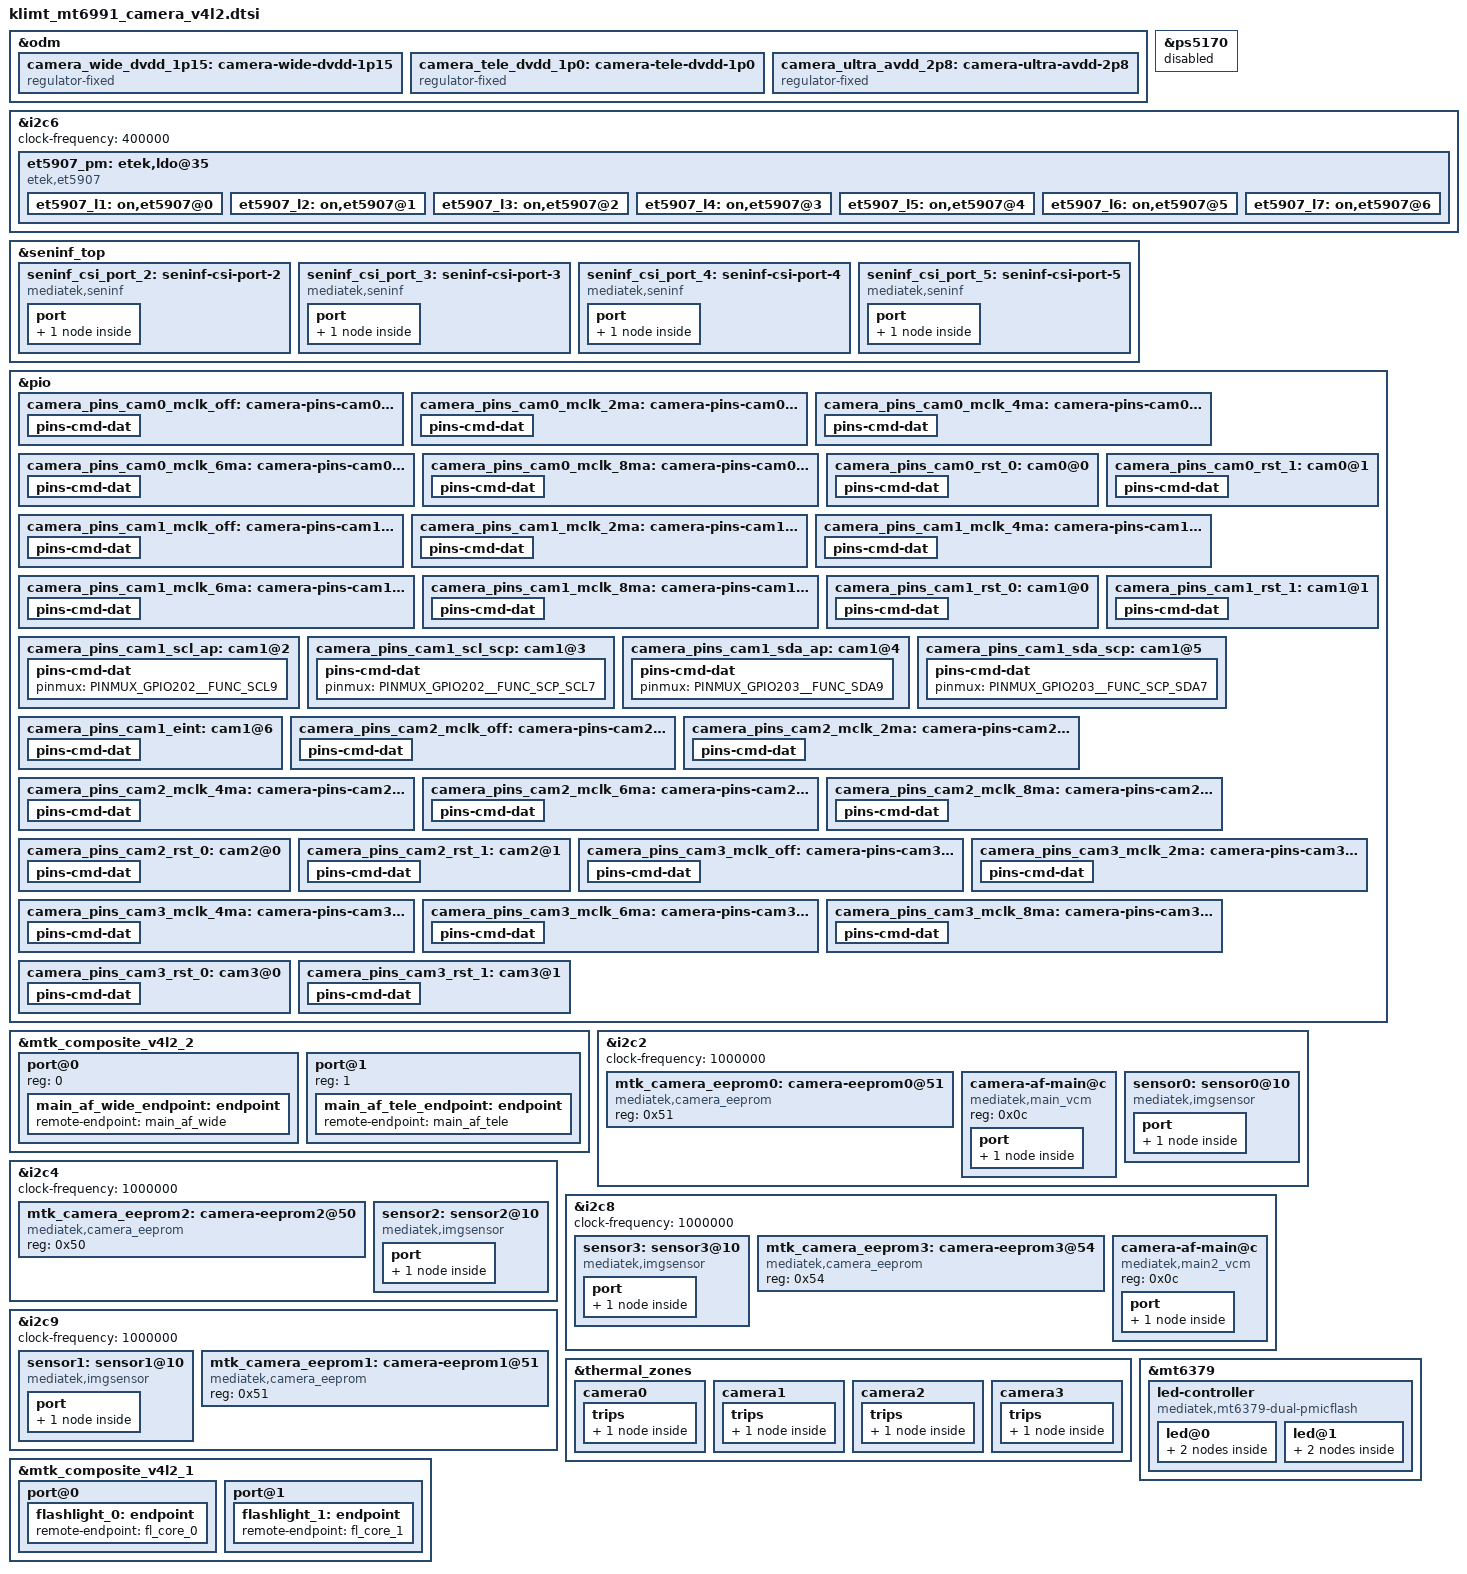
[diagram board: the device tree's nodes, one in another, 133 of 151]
// SPDX-License-Identifier: GPL-2.0
/* Copyright (c) 2023 MediaTek Inc. */
#include <dt-bindings/clock/mt6991-clk.h>
#include <dt-bindings/leds/common.h>
#include <dt-bindings/mfd/mt6379.h>

/* CAMERA GPIO fixed to regulator */
&odm {
	camera_wide_dvdd_1p15: camera-wide-dvdd-1p15 {
		compatible = "regulator-fixed";
		regulator-name = "camera-wide-dvdd-1p15";
		regulator-min-microvolt = <1150000>;
		regulator-max-microvolt = <1150000>;
		gpio = <&pio 180 0x0>;
		enable-active-high;
	};
	camera_tele_dvdd_1p0: camera-tele-dvdd-1p0 {
		compatible = "regulator-fixed";
		regulator-name = "camera-tele-dvdd-1p0";
		regulator-min-microvolt = <1000000>;
		regulator-max-microvolt = <1000000>;
		gpio = <&pio 181 0x0>;
		enable-active-high;
	};
	camera_ultra_avdd_2p8: camera-ultra-avdd-2p8 {
		compatible = "regulator-fixed";
		regulator-name = "camera-ultra-avdd-2p8";
		regulator-min-microvolt = <2800000>;
		regulator-max-microvolt = <2800000>;
		gpio = <&pio 207 0x0>;
		enable-active-high;
	};
};

&ps5170 {
	pinctrl-names = "enable", "disable";
	pinctrl-0 = <&ps_enable>;
	pinctrl-1 = <&ps_disable>;
	status = "disable";
};

&i2c6 {
	#address-cells = <1>;
	#size-cells = <0>;
	clock-frequency = <400000>;

	et5907_pm:etek,ldo@35 {
		compatible = "etek,et5907";
		reg = <0x35>;/*slave address*/
		index = <0>;

		et5907_l1:on,et5907@0{
			offset = /bits/ 16 <0x0000>;
			regulator-name ="et5907-l1";
			regulator-min-microvolt = <496000>;
			regulator-max-microvolt = <2048000>;
			min-dropout-voltage = <225000>;
			init-voltage = <1200000>;
			iout_ua = <650000>;
		};

		et5907_l2:on,et5907@1{
			offset = /bits/ 16 <0x0001>;
			regulator-name ="et5907-l2";
			regulator-min-microvolt = <496000>;
			regulator-max-microvolt = <2048000>;
			min-dropout-voltage = <225000>;
			init-voltage = <1200000>;
			iout_ua = <650000>;
		};

		et5907_l3:on,et5907@2{
			offset = /bits/ 16 <0x0002>;
			regulator-name ="et5907-l3";
			regulator-min-microvolt = <1372000>;
			regulator-max-microvolt = <3412000>;
			min-dropout-voltage = <200000>;
			init-voltage = <2800000>;
			iout_ua = <650000>;
		};

		et5907_l4:on,et5907@3{
			offset = /bits/ 16 <0x0003>;
			regulator-name ="et5907-l4";
			regulator-min-microvolt = <1372000>;
			regulator-max-microvolt = <3412000>;
			min-dropout-voltage = <200000>;
			init-voltage = <2800000>;
			iout_ua = <650000>;
		};

		et5907_l5:on,et5907@4{
			offset = /bits/ 16 <0x0004>;
			regulator-name ="et5907-l5";
			regulator-min-microvolt = <1372000>;
			regulator-max-microvolt = <3412000>;
			min-dropout-voltage = <300000>;
			init-voltage = <2800000>;
			iout_ua = <650000>;
		};

		et5907_l6:on,et5907@5{
			offset = /bits/ 16 <0x0005>;
			regulator-name ="et5907-l6";
			regulator-min-microvolt = <1372000>;
			regulator-max-microvolt = <3412000>;
			min-dropout-voltage = <300000>;
			init-voltage = <2800000>;
			iout_ua = <650000>;
		};

		et5907_l7:on,et5907@6{
			offset = /bits/ 16 <0x0006>;
			regulator-name ="et5907-l7";
			regulator-min-microvolt = <1372000>;
			regulator-max-microvolt = <3412000>;
			min-dropout-voltage = <300000>;
			init-voltage = <2800000>;
			iout_ua = <650000>;
		};

	};
};

&seninf_top {
		seninf_csi_port_2: seninf-csi-port-2 {
			compatible = "mediatek,seninf";
			csi-port = "2";

			nvmem-cells = <&csi_efuse2>;
			nvmem-cell-names = "rg_csi";

			port {
				seninf_csi_port_2_in: endpoint {
					remote-endpoint = <&sensor3_out>;
				};
			};
		};

		seninf_csi_port_3: seninf-csi-port-3 {
			compatible = "mediatek,seninf";
			csi-port = "3";

			nvmem-cells = <&csi_efuse3>;
			nvmem-cell-names = "rg_csi";

			port {
				seninf_csi_port_3_in: endpoint {
					remote-endpoint = <&sensor1_out>;
				};
			};
		};

		seninf_csi_port_4: seninf-csi-port-4 {
			compatible = "mediatek,seninf";
			csi-port = "4";

			nvmem-cells = <&csi_efuse4>;
			nvmem-cell-names = "rg_csi";

			port {
				seninf_csi_port_4_in: endpoint {
					remote-endpoint = <&sensor0_out>;
				};
			};
		};

		seninf_csi_port_5: seninf-csi-port-5 {
			compatible = "mediatek,seninf";
			csi-port = "5";

			nvmem-cells = <&csi_efuse5>;
			nvmem-cell-names = "rg_csi";

			port {
				seninf_csi_port_5_in: endpoint {
					remote-endpoint = <&sensor2_out>;
				};
			};
		};
};

/* CAMERA GPIO standardization */
&pio {
	camera_pins_cam0_mclk_off: camera-pins-cam0-mclk-off {
		pins-cmd-dat {
			pinmux = <PINMUX_GPIO196__FUNC_GPIO196>;
			drive-strength = <1>;
		};
	};
	camera_pins_cam0_mclk_2ma: camera-pins-cam0-mclk-2ma {
		pins-cmd-dat {
			pinmux = <PINMUX_GPIO196__FUNC_CMMCLK3>;
			drive-strength = <0>;
		};
	};
	camera_pins_cam0_mclk_4ma: camera-pins-cam0-mclk-4ma {
		pins-cmd-dat {
			pinmux = <PINMUX_GPIO196__FUNC_CMMCLK3>;
			drive-strength = <1>;
		};
	};
	camera_pins_cam0_mclk_6ma: camera-pins-cam0-mclk-6ma {
		pins-cmd-dat {
			pinmux = <PINMUX_GPIO196__FUNC_CMMCLK3>;
			drive-strength = <2>;
		};
	};
	camera_pins_cam0_mclk_8ma: camera-pins-cam0-mclk-8ma {
		pins-cmd-dat {
			pinmux = <PINMUX_GPIO196__FUNC_CMMCLK3>;
			drive-strength = <3>;
		};
	};
	camera_pins_cam0_rst_0: cam0@0 {
		pins-cmd-dat {
			pinmux = <PINMUX_GPIO197__FUNC_GPIO197>;
			drive-strength = <0>;
			output-low;
		};
	};
	camera_pins_cam0_rst_1: cam0@1 {
		pins-cmd-dat {
			pinmux = <PINMUX_GPIO197__FUNC_GPIO197>;
			drive-strength = <1>;
			output-high;
		};
	};
	camera_pins_cam1_mclk_off: camera-pins-cam1-mclk-off {
		pins-cmd-dat {
			pinmux = <PINMUX_GPIO79__FUNC_GPIO79>;
			drive-strength = <1>;
		};
	};
	camera_pins_cam1_mclk_2ma: camera-pins-cam1-mclk-2ma {
		pins-cmd-dat {
			pinmux = <PINMUX_GPIO79__FUNC_CMMCLK0>;
			drive-strength = <0>;
		};
	};
	camera_pins_cam1_mclk_4ma: camera-pins-cam1-mclk-4ma {
		pins-cmd-dat {
			pinmux = <PINMUX_GPIO79__FUNC_CMMCLK0>;
			drive-strength = <1>;
		};
	};
	camera_pins_cam1_mclk_6ma: camera-pins-cam1-mclk-6ma {
		pins-cmd-dat {
			pinmux = <PINMUX_GPIO79__FUNC_CMMCLK0>;
			drive-strength = <2>;
		};
	};
	camera_pins_cam1_mclk_8ma: camera-pins-cam1-mclk-8ma {
		pins-cmd-dat {
			pinmux = <PINMUX_GPIO79__FUNC_CMMCLK0>;
			drive-strength = <3>;
		};
	};
	camera_pins_cam1_rst_0: cam1@0 {
		pins-cmd-dat {
			pinmux = <PINMUX_GPIO204__FUNC_GPIO204>;
			slew-rate = <1>;
			output-low;
		};
	};
	camera_pins_cam1_rst_1: cam1@1 {
		pins-cmd-dat {
			pinmux = <PINMUX_GPIO204__FUNC_GPIO204>;
			slew-rate = <1>;
			output-high;
		};
	};
	camera_pins_cam1_scl_ap: cam1@2 {
		pins-cmd-dat {
			pinmux = <PINMUX_GPIO202__FUNC_SCL9>;
		};
	};
	camera_pins_cam1_scl_scp: cam1@3 {
		pins-cmd-dat {
			pinmux = <PINMUX_GPIO202__FUNC_SCP_SCL7>;
		};
	};
	camera_pins_cam1_sda_ap: cam1@4 {
		pins-cmd-dat {
			pinmux = <PINMUX_GPIO203__FUNC_SDA9>;
		};
	};
	camera_pins_cam1_sda_scp: cam1@5 {
		pins-cmd-dat {
			pinmux = <PINMUX_GPIO203__FUNC_SCP_SDA7>;
		};
	};
	camera_pins_cam1_eint: cam1@6 {
		pins-cmd-dat {
			pinmux = <PINMUX_GPIO41__FUNC_GPIO41>;
			bias-pull-up;
			input-enable;
		};
	};
	camera_pins_cam2_mclk_off: camera-pins-cam2-mclk-off {
		pins-cmd-dat {
			pinmux = <PINMUX_GPIO192__FUNC_GPIO192>;
			drive-strength = <1>;
		};
	};
	camera_pins_cam2_mclk_2ma: camera-pins-cam2-mclk-2ma {
		pins-cmd-dat {
			pinmux = <PINMUX_GPIO192__FUNC_CMMCLK2>;
			drive-strength = <0>;
		};
	};
	camera_pins_cam2_mclk_4ma: camera-pins-cam2-mclk-4ma {
		pins-cmd-dat {
			pinmux = <PINMUX_GPIO192__FUNC_CMMCLK2>;
			drive-strength = <1>;
		};
	};
	camera_pins_cam2_mclk_6ma: camera-pins-cam2-mclk-6ma {
		pins-cmd-dat {
			pinmux = <PINMUX_GPIO192__FUNC_CMMCLK2>;
			drive-strength = <2>;
		};
	};
	camera_pins_cam2_mclk_8ma: camera-pins-cam2-mclk-8ma {
		pins-cmd-dat {
			pinmux = <PINMUX_GPIO192__FUNC_CMMCLK2>;
			drive-strength = <3>;
		};
	};
	camera_pins_cam2_rst_0: cam2@0 {
		pins-cmd-dat {
			pinmux = <PINMUX_GPIO193__FUNC_GPIO193>;
			slew-rate = <1>;
			output-low;
		};
	};
	camera_pins_cam2_rst_1: cam2@1 {
		pins-cmd-dat {
			pinmux = <PINMUX_GPIO193__FUNC_GPIO193>;
			slew-rate = <1>;
			output-high;
		};
	};
	camera_pins_cam3_mclk_off: camera-pins-cam3-mclk-off {
		pins-cmd-dat {
			pinmux = <PINMUX_GPIO80__FUNC_GPIO80>;
			drive-strength = <1>;
		};
	};
	camera_pins_cam3_mclk_2ma: camera-pins-cam3-mclk-2ma {
		pins-cmd-dat {
			pinmux = <PINMUX_GPIO80__FUNC_CMMCLK1>;
			drive-strength = <0>;
		};
	};
	camera_pins_cam3_mclk_4ma: camera-pins-cam3-mclk-4ma {
		pins-cmd-dat {
			pinmux = <PINMUX_GPIO80__FUNC_CMMCLK1>;
			drive-strength = <1>;
		};
	};
	camera_pins_cam3_mclk_6ma: camera-pins-cam3-mclk-6ma {
		pins-cmd-dat {
			pinmux = <PINMUX_GPIO80__FUNC_CMMCLK1>;
			drive-strength = <2>;
		};
	};
	camera_pins_cam3_mclk_8ma: camera-pins-cam3-mclk-8ma {
		pins-cmd-dat {
			pinmux = <PINMUX_GPIO80__FUNC_CMMCLK1>;
			drive-strength = <3>;
		};
	};
	camera_pins_cam3_rst_0: cam3@0 {
		pins-cmd-dat {
			pinmux = <PINMUX_GPIO187__FUNC_GPIO187>;
			slew-rate = <1>;
			output-low;
		};
	};
	camera_pins_cam3_rst_1: cam3@1 {
		pins-cmd-dat {
			pinmux = <PINMUX_GPIO187__FUNC_GPIO187>;
			slew-rate = <1>;
			output-high;
		};
	};
};
/* CAMERA GPIO end */

&mtk_composite_v4l2_2 {
	#address-cells = <1>;
	#size-cells = <0>;
	port@0 {
		reg = <0>;
		main_af_wide_endpoint: endpoint {
			remote-endpoint = <&main_af_wide>;
		};
	};
	port@1 {
		reg = <1>;
		main_af_tele_endpoint: endpoint {
			remote-endpoint = <&main_af_tele>;
		};
    };
};

&i2c2 {
	status = "okay";
	clock-frequency = <1000000>;

	mtk_camera_eeprom0:camera-eeprom0@51 {
		compatible = "mediatek,camera_eeprom";
		reg = <0x51>;
		status = "okay";
	};

	camera-af-main@c {
		compatible = "mediatek,main_vcm";
		reg = <0x0c>;
		port {
			main_af_wide: endpoint {
				remote-endpoint = <&main_af_wide_endpoint>;
			};
		};
	};

	sensor0: sensor0@10 {
		compatible = "mediatek,imgsensor";
		sensor-names = "klimtovx9100wide_mipi_raw";
		reg = <0x10>;

		#thermal-sensor-cells = <0>;

		pinctrl-names = "mclk_off",
				"mclk_2mA",
				"mclk_4mA",
				"mclk_6mA",
				"mclk_8mA",
				"rst_low",
				"rst_high";
		pinctrl-0 = <&camera_pins_cam0_mclk_off>;
		pinctrl-1 = <&camera_pins_cam0_mclk_2ma>;
		pinctrl-2 = <&camera_pins_cam0_mclk_4ma>;
		pinctrl-3 = <&camera_pins_cam0_mclk_6ma>;
		pinctrl-4 = <&camera_pins_cam0_mclk_8ma>;
		pinctrl-5 = <&camera_pins_cam0_rst_0>;
		pinctrl-6 = <&camera_pins_cam0_rst_1>;

		avdd-supply = <&et5907_l4>;
		dvdd1-supply = <&mt6373_vbuck8>;
		dvdd-supply = <&camera_wide_dvdd_1p15>;
		dovdd-supply = <&mt6373_vrfio18_aif>;
		afvdd-supply = <&et5907_l3>;

		clocks = <&cksys_clk CLK_CK_UNIVPLL_192M_D32>,
			<&cksys_clk CLK_CK_UNIVPLL_192M_D16>,
			<&cksys_clk CLK_CK_F26M_CK_D2>,
			<&cksys_clk CLK_CK_UNIVPLL_192M_D10>,
			<&cksys_clk CLK_CK_UNIVPLL_192M_D8>,
			<&cksys_clk CLK_CK_UNIVPLL_D6_D16>,
			<&cksys_clk CLK_CK_OSC3>,
			<&cksys_clk CLK_CK_UNIVPLL_D6_D8>,
			<&vlp_cksys_clk CLK_VLP_CK_CAMTG3_SEL>;
		clock-names = "6", "12", "13", "19.2", "24", "26", "26_ulposc", "52", "mclk";

		status = "okay";
		port {
			sensor0_out: endpoint {
				remote-endpoint = <&seninf_csi_port_4_in>;
			};
		};
	};
};

&i2c4 {
	status = "okay";
	clock-frequency = <1000000>;

	mtk_camera_eeprom2:camera-eeprom2@50 {
		compatible = "mediatek,camera_eeprom";
		reg = <0x50>;
		status = "okay";
	};

	sensor2: sensor2@10 {
		compatible = "mediatek,imgsensor";
		sensor-names = "klimtov13bultra_mipi_raw";
		reg = <0x10>;

		#thermal-sensor-cells = <0>;

		pinctrl-names = "mclk_off",
				"mclk_2mA",
				"mclk_4mA",
				"mclk_6mA",
				"mclk_8mA",
				"rst_low",
				"rst_high";
		pinctrl-0 = <&camera_pins_cam3_mclk_off>;
		pinctrl-1 = <&camera_pins_cam3_mclk_2ma>;
		pinctrl-2 = <&camera_pins_cam3_mclk_4ma>;
		pinctrl-3 = <&camera_pins_cam3_mclk_6ma>;
		pinctrl-4 = <&camera_pins_cam3_mclk_8ma>;
		pinctrl-5 = <&camera_pins_cam3_rst_0>;
		pinctrl-6 = <&camera_pins_cam3_rst_1>;

		dvdd1-supply = <&mt6373_vbuck8>;
		avdd-supply = <&camera_ultra_avdd_2p8>;
		dvdd-supply = <&et5907_l1>;
		dovdd-supply = <&mt6373_vrfio18_aif>;

		clocks = <&cksys_clk CLK_CK_UNIVPLL_192M_D32>,
			<&cksys_clk CLK_CK_UNIVPLL_192M_D16>,
			<&cksys_clk CLK_CK_F26M_CK_D2>,
			<&cksys_clk CLK_CK_UNIVPLL_192M_D10>,
			<&cksys_clk CLK_CK_UNIVPLL_192M_D8>,
			<&cksys_clk CLK_CK_UNIVPLL_D6_D16>,
			<&cksys_clk CLK_CK_OSC3>,
			<&cksys_clk CLK_CK_UNIVPLL_D6_D8>,
			<&vlp_cksys_clk CLK_VLP_CK_CAMTG1_SEL>;
		clock-names = "6", "12", "13", "19.2", "24", "26", "26_ulposc", "52", "mclk";

		status = "okay";
		port {
			sensor2_out: endpoint {
				remote-endpoint = <&seninf_csi_port_5_in>;
			};
		};
	};

};

&i2c8 {
	status = "okay";
	clock-frequency = <1000000>;

	sensor3: sensor3@10 {
		compatible = "mediatek,imgsensor";
		sensor-names = "klimts5kjn5tele_mipi_raw","klimts5kjn5tele_v2_mipi_raw";
		reg = <0x10>;

		#thermal-sensor-cells = <0>;

		pinctrl-names = "mclk_off",
				"mclk_2mA",
				"mclk_4mA",
				"mclk_6mA",
				"mclk_8mA",
				"rst_low",
				"rst_high";
		pinctrl-0 = <&camera_pins_cam2_mclk_off>;
		pinctrl-1 = <&camera_pins_cam2_mclk_2ma>;
		pinctrl-2 = <&camera_pins_cam2_mclk_4ma>;
		pinctrl-3 = <&camera_pins_cam2_mclk_6ma>;
		pinctrl-4 = <&camera_pins_cam2_mclk_8ma>;
		pinctrl-5 = <&camera_pins_cam2_rst_0>;
		pinctrl-6 = <&camera_pins_cam2_rst_1>;

		dvdd1-supply = <&mt6373_vbuck8>;
		dvdd-supply = <&camera_tele_dvdd_1p0>;
		avdd-supply = <&et5907_l7>;
		dovdd-supply = <&mt6373_vrfio18_aif>;
		afvdd-supply = <&et5907_l5>;

		clocks = <&cksys_clk CLK_CK_UNIVPLL_192M_D32>,
			<&cksys_clk CLK_CK_UNIVPLL_192M_D16>,
			<&cksys_clk CLK_CK_F26M_CK_D2>,
			<&cksys_clk CLK_CK_UNIVPLL_192M_D10>,
			<&cksys_clk CLK_CK_UNIVPLL_192M_D8>,
			<&cksys_clk CLK_CK_UNIVPLL_D6_D16>,
			<&cksys_clk CLK_CK_OSC3>,
			<&cksys_clk CLK_CK_UNIVPLL_D6_D8>,
			<&vlp_cksys_clk CLK_VLP_CK_CAMTG2_SEL>;
		clock-names = "6", "12", "13", "19.2", "24", "26", "26_ulposc", "52", "mclk";

		status = "okay";
		port {
			sensor3_out: endpoint {
				remote-endpoint = <&seninf_csi_port_2_in>;
			};
		};
	};

	mtk_camera_eeprom3:camera-eeprom3@54 {
		compatible = "mediatek,camera_eeprom";
		reg = <0x54>;
		status = "okay";
	};

	camera-af-main@c {
		compatible = "mediatek,main2_vcm";
		reg = <0x0c>;
		port {
			main_af_tele: endpoint {
				remote-endpoint = <&main_af_tele_endpoint>;
			};
		};
	};
};

&i2c9 {
	status = "okay";
	clock-frequency = <1000000>;

	sensor1: sensor1@10 {
		compatible = "mediatek,imgsensor";
		sensor-names = "klimts5kkdsfront_mipi_raw";
		reg = <0x10>;

		pinctrl-names = "mclk1_off",
				"mclk1_2mA",
				"mclk1_4mA",
				"mclk1_6mA",
				"mclk1_8mA",
				"rst_low",
				"rst_high",
				"scl_ap",
				"scl_scp",
				"sda_ap",
				"sda_scp",
				"eint";
		pinctrl-0 = <&camera_pins_cam1_mclk_off>;
		pinctrl-1 = <&camera_pins_cam1_mclk_2ma>;
		pinctrl-2 = <&camera_pins_cam1_mclk_4ma>;
		pinctrl-3 = <&camera_pins_cam1_mclk_6ma>;
		pinctrl-4 = <&camera_pins_cam1_mclk_8ma>;
		pinctrl-5 = <&camera_pins_cam1_rst_0>;
		pinctrl-6 = <&camera_pins_cam1_rst_1>;
		pinctrl-7 = <&camera_pins_cam1_scl_ap>;
		pinctrl-8 = <&camera_pins_cam1_scl_scp>;
		pinctrl-9 = <&camera_pins_cam1_sda_ap>;
		pinctrl-10 = <&camera_pins_cam1_sda_scp>;
		pinctrl-11 = <&camera_pins_cam1_eint>;

		dvdd1-supply = <&mt6373_vbuck8>;
		avdd-supply = <&et5907_l6>;
		dvdd-supply = <&et5907_l2>;
		dovdd-supply = <&mt6373_vrfio18_aif>;

		clocks = <&cksys_clk CLK_CK_UNIVPLL_192M_D32>,
			<&cksys_clk CLK_CK_UNIVPLL_192M_D16>,
			<&cksys_clk CLK_CK_F26M_CK_D2>,
			<&cksys_clk CLK_CK_UNIVPLL_192M_D10>,
			<&cksys_clk CLK_CK_UNIVPLL_192M_D8>,
			<&cksys_clk CLK_CK_UNIVPLL_D6_D16>,
			<&cksys_clk CLK_CK_OSC3>,
			<&cksys_clk CLK_CK_UNIVPLL_D6_D8>,
			<&vlp_cksys_clk CLK_VLP_CK_CAMTG0_SEL>;
            clock-names = "6", "12", "13", "19.2", "24", "26", "26_ulposc", "52", "mclk";

		status = "okay";
		port {
			sensor1_out: endpoint {
				remote-endpoint = <&seninf_csi_port_3_in>;
			};
		};
	};

	mtk_camera_eeprom1:camera-eeprom1@51 {
		compatible = "mediatek,camera_eeprom";
		reg = <0x51>;
		status = "okay";
	};
};

&thermal_zones {
	camera0: camera0 {
		polling-delay = <0>; /* milliseconds */
		polling-delay-passive = <0>; /* milliseconds */
		thermal-sensors = <&sensor0>;
		trips {
			camera0_crit: camera0-crit {
				temperature = <120000>;
				hysteresis = <2000>;
				type = "passive";
			};
		};
	};
	camera1: camera1 {
		polling-delay = <0>; /* milliseconds */
		polling-delay-passive = <0>; /* milliseconds */
		thermal-sensors = <&sensor1>;
		trips {
			camera1_crit: camera1-crit {
				temperature = <120000>;
				hysteresis = <2000>;
				type = "passive";
			};
		};
	};
	camera2: camera2 {
		polling-delay = <0>; /* milliseconds */
		polling-delay-passive = <0>; /* milliseconds */
		thermal-sensors = <&sensor2>;
		trips {
			camera2_crit: camera2-crit {
				temperature = <120000>;
				hysteresis = <2000>;
				type = "passive";
			};
		};
	};
	camera3: camera3 {
		polling-delay = <0>; /* milliseconds */
		polling-delay-passive = <0>; /* milliseconds */
		thermal-sensors = <&sensor3>;
		trips {
			camera3_crit: camera3-crit {
				temperature = <120000>;
				hysteresis = <2000>;
				type = "passive";
			};
		};
	};
};

&mt6379{
	led-controller {
		compatible = "mediatek,mt6379-dual-pmicflash";
		#address-cells = <1>;
		#size-cells = <0>;
		interrupts = <MT6379_EVT_FLED_LVF> , <MT6379_EVT_FL_BUBO_VIN_THRO>,
					<MT6379_EVT_FL_THERMAL_THRO>, <MT6379_EVT_FL_BUBO_IL_THRO>,
					<MT6379_EVT_FLED3_SHORT>, <MT6379_EVT_FLED2_SHORT>,
					<MT6379_EVT_FLED1_SHORT>;
		interrupt-names = "fled_lvf", "fled_bubo_vin_thro",
					"fled_thermal_thro", "fled_bubo_il_thro",
					"fled3_short", "fled2_short",
					"fled1_short";
		led@0 {
			reg = <0>;
			function = LED_FUNCTION_FLASH;
			color = <LED_COLOR_ID_WHITE>;
			function-enumerator = <1>;
			led-max-microamp = <400000>;
			flash-max-microamp = <1500000>;
			type = <0>;
			ct = <0>;
			part = <0>;
			port@0 {
				fl_core_0: endpoint {
					remote-endpoint = <&flashlight_0>;
				};
			};
		};
		led@1 {
			reg = <1>;
			function = LED_FUNCTION_FLASH;
			color = <LED_COLOR_ID_WHITE>;
			function-enumerator = <2>;
			led-max-microamp = <400000>;
			flash-max-microamp = <1500000>;
			type = <0>;
			ct = <1>;
			part = <0>;
			port@1 {
				fl_core_1: endpoint {
					remote-endpoint = <&flashlight_1>;
				};
			};
		};
	};
};

&mtk_composite_v4l2_1 {
	port@0 {
			flashlight_0: endpoint {
				remote-endpoint = <&fl_core_0>;
			};
	};
	port@1 {
			flashlight_1: endpoint {
				remote-endpoint = <&fl_core_1>;
			};
	};
};
